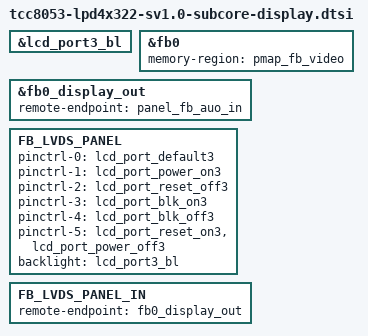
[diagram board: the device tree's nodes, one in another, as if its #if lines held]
// SPDX-License-Identifier: (GPL-2.0-or-later OR MIT)
/*
 * Copyright (C) 2023 Telechips Inc.
 */
#include <dt-bindings/display/tcc8053-lpd4x322-sv1.0-panel.h>
#include "tcc805x-subcore-disp-target-config.dtsi"
#include "tcc805x-subcore-vioc.dtsi"
#include "tcc805x-subcore-disp.dtsi"

#include "tcc805x-linux-ivi-subcore-vioc.dtsi"


#if defined(LCD_PORT3_BLK_GPIO) && defined(LCD_PORT3_BLK_NUM)
&lcd_port3_bl {
	status = "okay";
};
#endif


/* FB0 */
&fb0 {
	status = "okay";
	memory-region = <&pmap_fb_video>;
};

/* FB0 -> FB TM123XDHP90 */
&fb0_display_out {
	#if (FB_LVDS_PANEL_INDEX == LVDS_PANEL_AUO)
	remote-endpoint = <&panel_fb_auo_in>;
	#else
	remote-endpoint = <&panel_fb_boe_in>;
	#endif
};

/* FB TM123XDHP90 */
FB_LVDS_PANEL {
	status = "okay";
	#if defined(LCD_PORT3_PWR) && defined(LCD_PORT3_RST) && \
	    defined(LCD_PORT3_BLK)
	pinctrl-0 = <&lcd_port_default3>;
	pinctrl-1 = <&lcd_port_power_on3>;
	pinctrl-2 = <&lcd_port_reset_off3>;
	pinctrl-3 = <&lcd_port_blk_on3>;
	pinctrl-4 = <&lcd_port_blk_off3>;
	pinctrl-5 = <&lcd_port_reset_on3 &lcd_port_power_off3>;
	#endif
	#if defined(LCD_PORT3_BLK_GPIO) && defined(LCD_PORT3_BLK_NUM)
	backlight = <&lcd_port3_bl>;
	#endif
};

/* FB0 -> FB TM123XDHP90 */
FB_LVDS_PANEL_IN {
	remote-endpoint = <&fb0_display_out>;
};
/* end of file */
